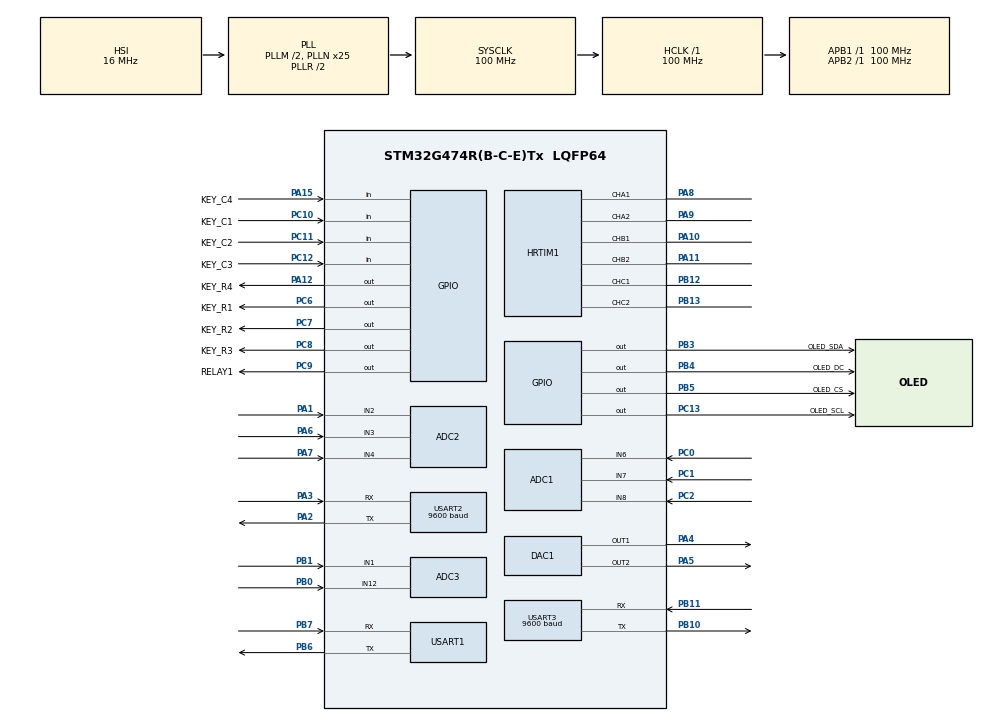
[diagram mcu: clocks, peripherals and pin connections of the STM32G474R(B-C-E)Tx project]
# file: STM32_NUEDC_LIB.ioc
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ADC1.Channel-12\#ChannelRegularConversion=ADC_CHANNEL_6
ADC1.Channel-13\#ChannelRegularConversion=ADC_CHANNEL_7
ADC1.Channel-17\#ChannelRegularConversion=ADC_CHANNEL_8
ADC1.ClockPrescaler=ADC_CLOCK_SYNC_PCLK_DIV4
ADC1.ContinuousConvMode=ENABLE
ADC1.DMAContinuousRequests=ENABLE
ADC1.EOCSelection=ADC_EOC_SEQ_CONV
ADC1.EnableAnalogWatchDog1=false
ADC1.EnableInjectedConversion=ENABLE
ADC1.EnableRegularConversion=ENABLE
ADC1.ExternalTrigInjecConv=ADC_EXTERNALTRIGINJEC_HRTIM_TRG2
ADC1.InjNumberOfConversion=3
ADC1.InjectedChannel-11\#ChannelInjectedConversion=ADC_CHANNEL_6
ADC1.InjectedChannel-14\#ChannelInjectedConversion=ADC_CHANNEL_7
ADC1.InjectedChannel-16\#ChannelInjectedConversion=ADC_CHANNEL_8
ADC1.InjectedConvMode=None
ADC1.InjectedOffsetNumber-11\#ChannelInjectedConversion=ADC_OFFSET_NONE
ADC1.InjectedOffsetNumber-14\#ChannelInjectedConversion=ADC_OFFSET_NONE
ADC1.InjectedOffsetNumber-16\#ChannelInjectedConversion=ADC_OFFSET_NONE
ADC1.InjectedRank-11\#ChannelInjectedConversion=1
ADC1.InjectedRank-14\#ChannelInjectedConversion=2
ADC1.InjectedRank-16\#ChannelInjectedConversion=3
ADC1.InjectedSamplingTime-11\#ChannelInjectedConversion=ADC_SAMPLETIME_47CYCLES_5
ADC1.InjectedSamplingTime-14\#ChannelInjectedConversion=ADC_SAMPLETIME_47CYCLES_5
ADC1.InjectedSamplingTime-16\#ChannelInjectedConversion=ADC_SAMPLETIME_47CYCLES_5
ADC1.NbrOfConversion=3
ADC1.NbrOfConversionFlag=1
ADC1.OffsetNumber-12\#ChannelRegularConversion=ADC_OFFSET_NONE
ADC1.OffsetNumber-13\#ChannelRegularConversion=ADC_OFFSET_NONE
ADC1.OffsetNumber-17\#ChannelRegularConversion=ADC_OFFSET_NONE
ADC1.Rank-12\#ChannelRegularConversion=1
ADC1.Rank-13\#ChannelRegularConversion=2
ADC1.Rank-17\#ChannelRegularConversion=3
ADC1.Rank2_Channel=ADC_CHANNEL_7
ADC1.Rank3_Channel=ADC_CHANNEL_8
ADC1.SamplingTime-12\#ChannelRegularConversion=ADC_SAMPLETIME_640CYCLES_5
ADC1.SamplingTime-13\#ChannelRegularConversion=ADC_SAMPLETIME_640CYCLES_5
ADC1.SamplingTime-17\#ChannelRegularConversion=ADC_SAMPLETIME_640CYCLES_5
ADC1.master=1
ADC2.Channel-12\#ChannelRegularConversion=ADC_CHANNEL_4
ADC2.Channel-6\#ChannelRegularConversion=ADC_CHANNEL_2
ADC2.Channel-7\#ChannelRegularConversion=ADC_CHANNEL_3
ADC2.ClockPrescaler=ADC_CLOCK_SYNC_PCLK_DIV4
ADC2.ContinuousConvMode=ENABLE
ADC2.DMAContinuousRequests=ENABLE
ADC2.EOCSelection=ADC_EOC_SEQ_CONV
ADC2.EnableInjectedConversion=ENABLE
ADC2.ExternalTrigInjecConv=ADC_EXTERNALTRIGINJEC_HRTIM_TRG4
ADC2.InjNumberOfConversion=3
ADC2.InjectedChannel-10\#ChannelInjectedConversion=ADC_CHANNEL_3
ADC2.InjectedChannel-11\#ChannelInjectedConversion=ADC_CHANNEL_4
ADC2.InjectedChannel-9\#ChannelInjectedConversion=ADC_CHANNEL_2
ADC2.InjectedOffsetNumber-10\#ChannelInjectedConversion=ADC_OFFSET_NONE
ADC2.InjectedOffsetNumber-11\#ChannelInjectedConversion=ADC_OFFSET_NONE
ADC2.InjectedOffsetNumber-9\#ChannelInjectedConversion=ADC_OFFSET_NONE
ADC2.InjectedRank-10\#ChannelInjectedConversion=2
ADC2.InjectedRank-11\#ChannelInjectedConversion=3
ADC2.InjectedRank-9\#ChannelInjectedConversion=1
ADC2.InjectedSamplingTime-10\#ChannelInjectedConversion=ADC_SAMPLETIME_47CYCLES_5
ADC2.InjectedSamplingTime-11\#ChannelInjectedConversion=ADC_SAMPLETIME_47CYCLES_5
ADC2.InjectedSamplingTime-9\#ChannelInjectedConversion=ADC_SAMPLETIME_47CYCLES_5
ADC2.NbrOfConversion=3
ADC2.NbrOfConversionFlag=1
ADC2.OffsetNumber-12\#ChannelRegularConversion=ADC_OFFSET_NONE
ADC2.OffsetNumber-6\#ChannelRegularConversion=ADC_OFFSET_NONE
ADC2.OffsetNumber-7\#ChannelRegularConversion=ADC_OFFSET_NONE
ADC2.Rank-12\#ChannelRegularConversion=3
ADC2.Rank-6\#ChannelRegularConversion=1
ADC2.Rank-7\#ChannelRegularConversion=2
ADC2.Rank1_Channel=ADC_CHANNEL_2
ADC2.Rank2_Channel=ADC_CHANNEL_3
ADC2.Rank3_Channel=ADC_CHANNEL_4
ADC2.SamplingTime-12\#ChannelRegularConversion=ADC_SAMPLETIME_640CYCLES_5
ADC2.SamplingTime-6\#ChannelRegularConversion=ADC_SAMPLETIME_640CYCLES_5
ADC2.SamplingTime-7\#ChannelRegularConversion=ADC_SAMPLETIME_640CYCLES_5
ADC3.Channel-0\#ChannelRegularConversion=ADC_CHANNEL_1
ADC3.Channel-4\#ChannelRegularConversion=ADC_CHANNEL_12
ADC3.ClockPrescaler=ADC_CLOCK_SYNC_PCLK_DIV4
ADC3.ContinuousConvMode=ENABLE
ADC3.DMAContinuousRequests=ENABLE
ADC3.EnableInjectedConversion=DISABLE
ADC3.ExternalTrigConv=ADC_EXTERNALTRIG_HRTIM_TRG3
ADC3.NbrOfConversion=2
ADC3.NbrOfConversionFlag=1
ADC3.OffsetNumber-0\#ChannelRegularConversion=ADC_OFFSET_NONE
ADC3.OffsetNumber-4\#ChannelRegularConversion=ADC_OFFSET_NONE
ADC3.Rank-0\#ChannelRegularConversion=1
ADC3.Rank-4\#ChannelRegularConversion=2
ADC3.Rank1_Channel=ADC_CHANNEL_1
ADC3.Rank2_Channel=ADC_CHANNEL_12
ADC3.Rank3_Channel=ADC_CHANNEL_1
ADC3.SamplingTime-0\#ChannelRegularConversion=ADC_SAMPLETIME_640CYCLES_5
ADC3.SamplingTime-4\#ChannelRegularConversion=ADC_SAMPLETIME_640CYCLES_5
ADC3.master=1
DAC1.DAC_Channel-DAC_OUT2=DAC_CHANNEL_2
DAC1.DAC_Trigger2_OUT1-DAC_OUT1=DAC_TRIGGER_NONE
DAC1.DAC_Trigger2_OUT2-DAC_OUT2=DAC_TRIGGER_NONE
DAC1.DAC_Trigger_OUT1-DAC_OUT1=DAC_TRIGGER_T6_TRGO
DAC1.DAC_Trigger_OUT2-DAC_OUT2=DAC_TRIGGER_T7_TRGO
Dma.ADC1.2.Direction=DMA_PERIPH_TO_MEMORY
Dma.ADC1.2.EventEnable=DISABLE
Dma.ADC1.2.Instance=DMA1_Channel3
Dma.ADC1.2.MemDataAlignment=DMA_MDATAALIGN_WORD
Dma.ADC1.2.MemInc=DMA_MINC_ENABLE
Dma.ADC1.2.Mode=DMA_CIRCULAR
Dma.ADC1.2.PeriphDataAlignment=DMA_PDATAALIGN_WORD
Dma.ADC1.2.PeriphInc=DMA_PINC_DISABLE
Dma.ADC1.2.Polarity=HAL_DMAMUX_REQ_GEN_RISING
Dma.ADC1.2.Priority=DMA_PRIORITY_LOW
Dma.ADC1.2.RequestNumber=1
Dma.ADC1.2.SignalID=NONE
Dma.ADC1.2.SyncEnable=DISABLE
Dma.ADC1.2.SyncPolarity=HAL_DMAMUX_SYNC_NO_EVENT
Dma.ADC1.2.SyncRequestNumber=1
Dma.ADC1.2.SyncSignalID=NONE
Dma.ADC2.4.Direction=DMA_PERIPH_TO_MEMORY
Dma.ADC2.4.EventEnable=DISABLE
Dma.ADC2.4.Instance=DMA1_Channel4
Dma.ADC2.4.MemDataAlignment=DMA_MDATAALIGN_WORD
Dma.ADC2.4.MemInc=DMA_MINC_ENABLE
Dma.ADC2.4.Mode=DMA_CIRCULAR
Dma.ADC2.4.PeriphDataAlignment=DMA_PDATAALIGN_WORD
Dma.ADC2.4.PeriphInc=DMA_PINC_DISABLE
Dma.ADC2.4.Polarity=HAL_DMAMUX_REQ_GEN_RISING
Dma.ADC2.4.Priority=DMA_PRIORITY_LOW
Dma.ADC2.4.RequestNumber=1
Dma.ADC2.4.SignalID=NONE
Dma.ADC2.4.SyncEnable=DISABLE
Dma.ADC2.4.SyncPolarity=HAL_DMAMUX_SYNC_NO_EVENT
Dma.ADC2.4.SyncRequestNumber=1
Dma.ADC2.4.SyncSignalID=NONE
Dma.ADC3.3.Direction=DMA_PERIPH_TO_MEMORY
Dma.ADC3.3.EventEnable=DISABLE
Dma.ADC3.3.Instance=DMA1_Channel5
Dma.ADC3.3.MemDataAlignment=DMA_MDATAALIGN_WORD
Dma.ADC3.3.MemInc=DMA_MINC_ENABLE
Dma.ADC3.3.Mode=DMA_CIRCULAR
Dma.ADC3.3.PeriphDataAlignment=DMA_PDATAALIGN_WORD
Dma.ADC3.3.PeriphInc=DMA_PINC_DISABLE
Dma.ADC3.3.Polarity=HAL_DMAMUX_REQ_GEN_RISING
Dma.ADC3.3.Priority=DMA_PRIORITY_LOW
Dma.ADC3.3.RequestNumber=1
Dma.ADC3.3.SignalID=NONE
Dma.ADC3.3.SyncEnable=DISABLE
Dma.ADC3.3.SyncPolarity=HAL_DMAMUX_SYNC_NO_EVENT
Dma.ADC3.3.SyncRequestNumber=1
Dma.ADC3.3.SyncSignalID=NONE
Dma.DAC1_CH1.5.Direction=DMA_MEMORY_TO_PERIPH
Dma.DAC1_CH1.5.EventEnable=DISABLE
Dma.DAC1_CH1.5.Instance=DMA1_Channel6
Dma.DAC1_CH1.5.MemDataAlignment=DMA_MDATAALIGN_WORD
Dma.DAC1_CH1.5.MemInc=DMA_MINC_ENABLE
Dma.DAC1_CH1.5.Mode=DMA_CIRCULAR
Dma.DAC1_CH1.5.PeriphDataAlignment=DMA_PDATAALIGN_WORD
Dma.DAC1_CH1.5.PeriphInc=DMA_PINC_DISABLE
Dma.DAC1_CH1.5.Polarity=HAL_DMAMUX_REQ_GEN_RISING
Dma.DAC1_CH1.5.Priority=DMA_PRIORITY_LOW
Dma.DAC1_CH1.5.RequestNumber=1
Dma.DAC1_CH1.5.SignalID=NONE
Dma.DAC1_CH1.5.SyncEnable=DISABLE
Dma.DAC1_CH1.5.SyncPolarity=HAL_DMAMUX_SYNC_NO_EVENT
Dma.DAC1_CH1.5.SyncRequestNumber=1
Dma.DAC1_CH1.5.SyncSignalID=NONE
Dma.DAC1_CH2.6.Direction=DMA_MEMORY_TO_PERIPH
Dma.DAC1_CH2.6.EventEnable=DISABLE
Dma.DAC1_CH2.6.Instance=DMA1_Channel7
Dma.DAC1_CH2.6.MemDataAlignment=DMA_MDATAALIGN_WORD
Dma.DAC1_CH2.6.MemInc=DMA_MINC_ENABLE
Dma.DAC1_CH2.6.Mode=DMA_CIRCULAR
Dma.DAC1_CH2.6.PeriphDataAlignment=DMA_PDATAALIGN_WORD
Dma.DAC1_CH2.6.PeriphInc=DMA_PINC_DISABLE
Dma.DAC1_CH2.6.Polarity=HAL_DMAMUX_REQ_GEN_RISING
Dma.DAC1_CH2.6.Priority=DMA_PRIORITY_LOW
Dma.DAC1_CH2.6.RequestNumber=1
Dma.DAC1_CH2.6.SignalID=NONE
Dma.DAC1_CH2.6.SyncEnable=DISABLE
Dma.DAC1_CH2.6.SyncPolarity=HAL_DMAMUX_SYNC_NO_EVENT
Dma.DAC1_CH2.6.SyncRequestNumber=1
Dma.DAC1_CH2.6.SyncSignalID=NONE
Dma.Request0=USART1_RX
Dma.Request1=USART1_TX
Dma.Request2=ADC1
Dma.Request3=ADC3
Dma.Request4=ADC2
Dma.Request5=DAC1_CH1
Dma.Request6=DAC1_CH2
Dma.Request7=USART2_RX
Dma.Request8=USART3_RX
Dma.USART1_RX.0.Direction=DMA_PERIPH_TO_MEMORY
Dma.USART1_RX.0.EventEnable=DISABLE
Dma.USART1_RX.0.Instance=DMA1_Channel1
Dma.USART1_RX.0.MemDataAlignment=DMA_MDATAALIGN_BYTE
Dma.USART1_RX.0.MemInc=DMA_MINC_ENABLE
Dma.USART1_RX.0.Mode=DMA_NORMAL
Dma.USART1_RX.0.PeriphDataAlignment=DMA_PDATAALIGN_BYTE
Dma.USART1_RX.0.PeriphInc=DMA_PINC_DISABLE
Dma.USART1_RX.0.Polarity=HAL_DMAMUX_REQ_GEN_RISING
Dma.USART1_RX.0.Priority=DMA_PRIORITY_LOW
Dma.USART1_RX.0.RequestNumber=1
Dma.USART1_RX.0.SignalID=NONE
Dma.USART1_RX.0.SyncEnable=DISABLE
Dma.USART1_RX.0.SyncPolarity=HAL_DMAMUX_SYNC_NO_EVENT
Dma.USART1_RX.0.SyncRequestNumber=1
Dma.USART1_RX.0.SyncSignalID=NONE
Dma.USART1_TX.1.Direction=DMA_MEMORY_TO_PERIPH
Dma.USART1_TX.1.EventEnable=DISABLE
Dma.USART1_TX.1.Instance=DMA1_Channel2
Dma.USART1_TX.1.MemDataAlignment=DMA_MDATAALIGN_BYTE
Dma.USART1_TX.1.MemInc=DMA_MINC_ENABLE
Dma.USART1_TX.1.Mode=DMA_NORMAL
Dma.USART1_TX.1.PeriphDataAlignment=DMA_PDATAALIGN_BYTE
Dma.USART1_TX.1.PeriphInc=DMA_PINC_DISABLE
Dma.USART1_TX.1.Polarity=HAL_DMAMUX_REQ_GEN_RISING
Dma.USART1_TX.1.Priority=DMA_PRIORITY_LOW
Dma.USART1_TX.1.RequestNumber=1
Dma.USART1_TX.1.SignalID=NONE
Dma.USART1_TX.1.SyncEnable=DISABLE
Dma.USART1_TX.1.SyncPolarity=HAL_DMAMUX_SYNC_NO_EVENT
Dma.USART1_TX.1.SyncRequestNumber=1
Dma.USART1_TX.1.SyncSignalID=NONE
Dma.USART2_RX.7.Direction=DMA_PERIPH_TO_MEMORY
Dma.USART2_RX.7.EventEnable=DISABLE
Dma.USART2_RX.7.Instance=DMA1_Channel8
Dma.USART2_RX.7.MemDataAlignment=DMA_MDATAALIGN_BYTE
Dma.USART2_RX.7.MemInc=DMA_MINC_ENABLE
Dma.USART2_RX.7.Mode=DMA_NORMAL
Dma.USART2_RX.7.PeriphDataAlignment=DMA_PDATAALIGN_BYTE
Dma.USART2_RX.7.PeriphInc=DMA_PINC_DISABLE
Dma.USART2_RX.7.Polarity=HAL_DMAMUX_REQ_GEN_RISING
Dma.USART2_RX.7.Priority=DMA_PRIORITY_LOW
Dma.USART2_RX.7.RequestNumber=1
Dma.USART2_RX.7.SignalID=NONE
Dma.USART2_RX.7.SyncEnable=DISABLE
Dma.USART2_RX.7.SyncPolarity=HAL_DMAMUX_SYNC_NO_EVENT
Dma.USART2_RX.7.SyncRequestNumber=1
Dma.USART2_RX.7.SyncSignalID=NONE
Dma.USART3_RX.8.Direction=DMA_PERIPH_TO_MEMORY
Dma.USART3_RX.8.EventEnable=DISABLE
Dma.USART3_RX.8.Instance=DMA2_Channel1
Dma.USART3_RX.8.MemDataAlignment=DMA_MDATAALIGN_BYTE
Dma.USART3_RX.8.MemInc=DMA_MINC_ENABLE
Dma.USART3_RX.8.Mode=DMA_NORMAL
Dma.USART3_RX.8.PeriphDataAlignment=DMA_PDATAALIGN_BYTE
Dma.USART3_RX.8.PeriphInc=DMA_PINC_DISABLE
Dma.USART3_RX.8.Polarity=HAL_DMAMUX_REQ_GEN_RISING
Dma.USART3_RX.8.Priority=DMA_PRIORITY_LOW
Dma.USART3_RX.8.RequestNumber=1
Dma.USART3_RX.8.SignalID=NONE
Dma.USART3_RX.8.SyncEnable=DISABLE
Dma.USART3_RX.8.SyncPolarity=HAL_DMAMUX_SYNC_NO_EVENT
Dma.USART3_RX.8.SyncRequestNumber=1
Dma.USART3_RX.8.SyncSignalID=NONE
HRTIM1.ADCTrigger2_Source1=HRTIM_ADCTRIGGEREVENT24_TIMERA_PERIOD
HRTIM1.ADCTrigger4_Source1=HRTIM_ADCTRIGGEREVENT24_TIMERB_PERIOD
HRTIM1.ADCTrigger_Id1=__NULL
HRTIM1.ADCTrigger_Id2=HRTIM_ADCTRIGGER_2
HRTIM1.ADCTrigger_Id3=__NULL
HRTIM1.ADCTrigger_Id4=HRTIM_ADCTRIGGER_4
HRTIM1.Adrom_TC=HRTIM_TIM_ADROM_CREST
HRTIM1.CompareUnit1-Output_TA1TA2=__NULL
HRTIM1.CompareUnit2-Output_TA1TA2=HRTIM_COMPAREUNIT_2
HRTIM1.CompareUnit2-Output_TB1TB2=HRTIM_COMPAREUNIT_2
HRTIM1.CompareUnit2-Output_TC1TC2=HRTIM_COMPAREUNIT_2
HRTIM1.CompareUnit3-Output_TC1TC2=__NULL
HRTIM1.CompareUnit4-Output_TB1TB2=__NULL
HRTIM1.CompareValue2-Output_TA1TA2=10000
HRTIM1.CompareValue2-Output_TB1TB2=5000
HRTIM1.CompareValue2-Output_TC1TC2=2000
HRTIM1.DeadTimeInsertion-Output_TA1TA2=HRTIM_TIMDEADTIMEINSERTION_ENABLED
HRTIM1.DeadTimeInsertion-Output_TB1TB2=HRTIM_TIMDEADTIMEINSERTION_ENABLED
HRTIM1.DeadTimeInsertion-Output_TC1TC2=HRTIM_TIMDEADTIMEINSERTION_ENABLED
HRTIM1.Deadtimeconfig-Output_TC1TC2=HRTIM_TIMERINDEX_TIMER_C
HRTIM1.Event_EEV1=__NULL
HRTIM1.Event_EEV2=__NULL
HRTIM1.FallingValue-Output_TA1TA2=50
HRTIM1.FallingValue-Output_TB1TB2=50
HRTIM1.FallingValue-Output_TC1TC2=50
HRTIM1.Ferom_TC=HRTIM_TIM_FEROM_VALLEY
HRTIM1.HRTIMInterruptResquests1=HRTIM_IT_NONE
HRTIM1.HRTIMInterruptResquests2=HRTIM_IT_NONE
HRTIM1.InterruptRequests1-Output_TC1TC2=HRTIM_TIM_IT_RST
HRTIM1.NumberADCTriggerSource2=1
HRTIM1.NumberADCTriggerSource4=1
HRTIM1.NumberInterruptRequests-Output_TC1TC2=1
HRTIM1.NumberResetSource1-Output_TA1TA2=1
HRTIM1.NumberResetSource1-Output_TB1TB2=1
HRTIM1.NumberResetSource1-Output_TC1TC2=1
HRTIM1.NumberResetSource2_TC=0
HRTIM1.NumberResetTrigger-Output_TA1TA2=0
HRTIM1.NumberSetSource1-Output_TA1TA2=1
HRTIM1.NumberSetSource1-Output_TB1TB2=1
HRTIM1.NumberSetSource1-Output_TC1TC2=1
HRTIM1.NumberSetSource2_TA=0
HRTIM1.NumberSetSource2_TC=0
HRTIM1.ORingUpdateSource_ADCTrigger4=HRTIM_ADCTRIGGERUPDATE_TIMER_B
HRTIM1.Outrom_TC=HRTIM_TIM_OUTROM_VALLEY
HRTIM1.Periode_TA=2500
HRTIM1.Periode_TB=5000
HRTIM1.Periode_TC=2000
HRTIM1.PrescalerDead-Output_TA1TA2=HRTIM_TIMDEADTIME_PRESCALERRATIO_DIV1
HRTIM1.PrescalerDead-Output_TB1TB2=HRTIM_TIMDEADTIME_PRESCALERRATIO_DIV1
HRTIM1.PrescalerDead-Output_TC1TC2=HRTIM_TIMDEADTIME_PRESCALERRATIO_DIV1
HRTIM1.PrescalerRatio_TA=HRTIM_PRESCALERRATIO_DIV1
HRTIM1.PrescalerRatio_TB=HRTIM_PRESCALERRATIO_DIV1
HRTIM1.PrescalerRatio_TC=HRTIM_PRESCALERRATIO_DIV1
HRTIM1.ResetOutput1_Source1-Output_TA1TA2=HRTIM_OUTPUTRESET_TIMCMP2
HRTIM1.ResetOutput1_Source1-Output_TB1TB2=HRTIM_OUTPUTRESET_TIMCMP2
HRTIM1.ResetOutput1_Source1-Output_TC1TC2=HRTIM_OUTPUTRESET_TIMCMP2
HRTIM1.RisingValue-Output_TA1TA2=50
HRTIM1.RisingValue-Output_TB1TB2=50
HRTIM1.RisingValue-Output_TC1TC2=50
HRTIM1.SetOutput1_Source1-Output_TA1TA2=HRTIM_OUTPUTSET_TIMPER
HRTIM1.SetOutput1_Source1-Output_TB1TB2=HRTIM_OUTPUTSET_TIMPER
HRTIM1.SetOutput1_Source1-Output_TC1TC2=HRTIM_OUTPUTSET_TIMPER
HRTIM1.UpDownMode-Output_TC1TC2=HRTIM_TIMERUPDOWNMODE_UPDOWN
HRTIM1.postscaler2=0
HRTIM1.rom_TC=HRTIM_TIM_ROM_CREST
Mcu.Family=STM32G4
Mcu.Name=STM32G474R(B-C-E)Tx
Mcu.Package=LQFP64
NVIC.ADC1_2_IRQn=true\:0\:0\:false\:false\:true\:true\:true\:true
NVIC.ADC3_IRQn=true\:0\:0\:false\:false\:true\:true\:true\:true
NVIC.DMA1_Channel1_IRQn=true\:0\:0\:false\:false\:true\:false\:true\:true
NVIC.DMA1_Channel2_IRQn=true\:0\:0\:false\:false\:true\:false\:true\:true
NVIC.DMA1_Channel3_IRQn=true\:1\:0\:true\:false\:true\:false\:true\:true
NVIC.DMA1_Channel4_IRQn=true\:1\:0\:true\:false\:true\:false\:true\:true
NVIC.DMA1_Channel5_IRQn=true\:1\:0\:true\:false\:true\:false\:true\:true
NVIC.DMA1_Channel6_IRQn=true\:0\:0\:false\:false\:true\:false\:true\:true
NVIC.DMA1_Channel7_IRQn=true\:0\:0\:false\:false\:true\:false\:true\:true
NVIC.DMA1_Channel8_IRQn=true\:0\:0\:false\:false\:true\:false\:true\:true
NVIC.DMA2_Channel1_IRQn=true\:0\:0\:false\:false\:true\:false\:true\:true
NVIC.HRTIM1_TIMC_IRQn=true\:0\:0\:false\:false\:true\:true\:true\:true
NVIC.PriorityGroup=NVIC_PRIORITYGROUP_4
NVIC.TIM1_UP_TIM16_IRQn=true\:0\:0\:false\:false\:true\:true\:true\:true
NVIC.TIM6_DAC_IRQn=true\:0\:0\:false\:false\:true\:true\:true\:true
NVIC.TIM7_DAC_IRQn=true\:0\:0\:false\:false\:true\:true\:true\:true
NVIC.TIM8_UP_IRQn=true\:0\:0\:false\:false\:true\:true\:true\:true
NVIC.USART1_IRQn=true\:0\:0\:true\:false\:true\:true\:true\:true
NVIC.USART2_IRQn=true\:0\:0\:false\:false\:true\:true\:true\:true
NVIC.USART3_IRQn=true\:0\:0\:false\:false\:true\:true\:true\:true
PA1.Mode=IN2-Single-Ended
PA1.Signal=ADC2_IN2
PA10.Mode=Output_TB1TB2
PA10.Signal=HRTIM1_CHB1
PA11.Mode=Output_TB1TB2
PA11.Signal=HRTIM1_CHB2
PA12.GPIO_Label=KEY_R4
PA12.Signal=GPIO_Output
PA13.Mode=Serial_Wire
PA13.Signal=SYS_JTMS-SWDIO
PA14.Mode=Serial_Wire
PA14.Signal=SYS_JTCK-SWCLK
PA15.GPIO_Label=KEY_C4
PA15.GPIO_PuPd=GPIO_PULLDOWN
PA15.Signal=GPIO_Input
PA2.Mode=Asynchronous
PA2.Signal=USART2_TX
PA3.Mode=Asynchronous
PA3.Signal=USART2_RX
PA4.Signal=COMP_DAC11_group
PA5.Signal=COMP_DAC12_group
PA6.Mode=IN3-Single-Ended
PA6.Signal=ADC2_IN3
PA7.Mode=IN4-Single-Ended
PA7.Signal=ADC2_IN4
PA8.Mode=Output_TA1TA2
PA8.Signal=HRTIM1_CHA1
PA9.Mode=Output_TA1TA2
PA9.Signal=HRTIM1_CHA2
PB0.Mode=IN12-Single-Ended
PB0.Signal=ADC3_IN12
PB1.Mode=IN1-Single-Ended
PB1.Signal=ADC3_IN1
PB10.Mode=Asynchronous
PB10.Signal=USART3_TX
PB11.Mode=Asynchronous
PB11.Signal=USART3_RX
PB12.Mode=Output_TC1TC2
PB12.Signal=HRTIM1_CHC1
PB13.Mode=Output_TC1TC2
PB13.Signal=HRTIM1_CHC2
PB3.GPIO_Label=OLED_SDA
PB3.GPIO_Speed=GPIO_SPEED_FREQ_VERY_HIGH
PB3.Signal=GPIO_Output
PB4.GPIO_Label=OLED_DC
PB4.GPIO_Speed=GPIO_SPEED_FREQ_VERY_HIGH
PB4.Signal=GPIO_Output
PB5.GPIO_Label=OLED_CS
PB5.GPIO_Speed=GPIO_SPEED_FREQ_VERY_HIGH
PB5.Signal=GPIO_Output
PB6.Mode=Asynchronous
PB6.Signal=USART1_TX
PB7.Mode=Asynchronous
PB7.Signal=USART1_RX
PC0.Mode=IN6-Single-Ended
PC0.Signal=ADC1_IN6
PC1.Mode=IN7-Single-Ended
PC1.Signal=ADC1_IN7
PC10.GPIO_Label=KEY_C1
PC10.GPIO_PuPd=GPIO_PULLDOWN
PC10.Signal=GPIO_Input
PC11.GPIO_Label=KEY_C2
PC11.GPIO_PuPd=GPIO_PULLDOWN
PC11.Signal=GPIO_Input
PC12.GPIO_Label=KEY_C3
PC12.GPIO_PuPd=GPIO_PULLDOWN
PC12.Signal=GPIO_Input
PC13.GPIO_Label=OLED_SCL
PC13.Signal=GPIO_Output
PC2.Mode=IN8-Single-Ended
PC2.Signal=ADC1_IN8
PC6.GPIO_Label=KEY_R1
PC6.Signal=GPIO_Output
PC7.GPIO_Label=KEY_R2
PC7.Signal=GPIO_Output
PC8.GPIO_Label=KEY_R3
PC8.Signal=GPIO_Output
PC9.GPIO_Label=RELAY1
PC9.PinState=GPIO_PIN_SET
PC9.Signal=GPIO_Output
PF0-OSC_IN.Mode=HSE-External-Oscillator
PF0-OSC_IN.Signal=RCC_OSC_IN
PF1-OSC_OUT.Mode=HSE-External-Oscillator
PF1-OSC_OUT.Signal=RCC_OSC_OUT
ProjectManager.HeapSize=0x200
ProjectManager.StackSize=0x400
ProjectManager.TargetToolchain=STM32CubeIDE
RCC.ADC12Freq_Value=100000000
RCC.ADC345Freq_Value=100000000
RCC.AHBFreq_Value=100000000
RCC.APB1Freq_Value=100000000
RCC.APB1TimFreq_Value=100000000
RCC.APB2Freq_Value=100000000
RCC.APB2TimFreq_Value=100000000
RCC.CortexFreq_Value=100000000
RCC.EXTERNAL_CLOCK_VALUE=12288000
RCC.HCLKFreq_Value=100000000
RCC.HSE_VALUE=8000000
RCC.HSI48_VALUE=48000000
RCC.HSI_VALUE=16000000
RCC.LSE_VALUE=32768
RCC.PLLM=RCC_PLLM_DIV2
RCC.PLLN=25
RCC.SYSCLKFreq_VALUE=100000000
RCC.SYSCLKSource=RCC_SYSCLKSOURCE_PLLCLK
RCC.USBFreq_Value=100000000
RCC.VCOOutputFreq_Value=200000000
SH.COMP_DAC11_group.0=DAC1_OUT1,DAC_OUT1
SH.COMP_DAC12_group.0=DAC1_OUT2,DAC_OUT2
STMicroelectronics.X-CUBE-ALGOBUILD.1.3.0.LibraryCcDSPOoLibraryJjDSPOoLibrary=true
TIM1.AutoReloadPreload=TIM_AUTORELOAD_PRELOAD_ENABLE
TIM1.PeriodNoDither=50000-1
TIM6.AutoReloadPreload=TIM_AUTORELOAD_PRELOAD_ENABLE
TIM6.PeriodNoDither=5000-1
TIM6.Prescaler=0
TIM6.TIM_MasterOutputTrigger=TIM_TRGO_UPDATE
TIM7.AutoReloadPreload=TIM_AUTORELOAD_PRELOAD_ENABLE
TIM7.PeriodNoDither=5000-1
TIM7.Prescaler=10-1
TIM7.TIM_MasterOutputTrigger=TIM_TRGO_UPDATE
TIM8.AutoReloadPreload=TIM_AUTORELOAD_PRELOAD_ENABLE
TIM8.PeriodNoDither=100-1
USART1.VirtualMode-Asynchronous=VM_ASYNC
USART2.BaudRate=9600
USART2.VirtualMode-Asynchronous=VM_ASYNC
USART3.BaudRate=9600
USART3.VirtualMode-Asynchronous=VM_ASYNC
VP_STMicroelectronics.X-CUBE-ALGOBUILD_VS_DSPOoLibraryJjLibrary_1.3.0_1.3.0.Mode=DSPOoLibraryJjLibrary
VP_SYS_VS_DBSignals.Mode=DisableDeadBatterySignals
VP_TIM1_VS_ClockSourceINT.Mode=Internal
VP_TIM6_VS_ClockSourceINT.Mode=Enable_Timer
VP_TIM7_VS_ClockSourceINT.Mode=Enable_Timer
VP_TIM8_VS_ClockSourceINT.Mode=Internal
board=custom

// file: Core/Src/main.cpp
/* USER CODE BEGIN Header */
/**
 ******************************************************************************
 * @file           : main.c
 * @brief          : Main program body
 ******************************************************************************
 * @attention
 *
 * Copyright (c) 2025 STMicroelectronics.
 * All rights reserved.
 *
 * This software is licensed under terms that can be found in the LICENSE file
 * in the root directory of this software component.
 * If no LICENSE file comes with this software, it is provided AS-IS.
 *
 ******************************************************************************
 */
/* USER CODE END Header */
#include "main.h"
#include "adc.h"
#include "dac.h"
#include "dma.h"
#include "hrtim.h"
#include "tim.h"
#include "usart.h"
#include "gpio.h"
/* USER CODE BEGIN Includes */
#include "stm32_hrtim_pwm.h"
#include "stm32_adc.h"
#include "stm32_relay.h"
#include "stm32_test.h"
#include "stm32_message.h"
#include "stm32_dc_dc.h"
#include "SEGGER_SYSVIEW.h"
#include "SEGGER_SYSVIEW_Conf.h"
#include "2015.h"
#include "flt_fir_hilbert.h"
#include "hw_port_dac.h"
/* USER CODE END Includes */

void SystemClock_Config(void);

int main(void)
{

  /* MCU Configuration--------------------------------------------------------*/

  /* Reset of all peripherals, Initializes the Flash interface and the Systick. */
  HAL_Init();

  /* Configure the system clock */
  SystemClock_Config();

  /* USER CODE BEGIN SysInit */
//  stm32_test::segger_systemview_test_enable();
  /* USER CODE END SysInit */

  /* Initialize all configured peripherals */
  MX_GPIO_Init();
  MX_DMA_Init();
  MX_ADC1_Init();
  MX_HRTIM1_Init();
  MX_USART1_UART_Init();
  MX_ADC2_Init();
  MX_ADC3_Init();
  MX_TIM1_Init();
  MX_DAC1_Init();
  MX_TIM6_Init();
  MX_TIM7_Init();
  MX_TIM8_Init();
  MX_USART2_UART_Init();
  MX_USART3_UART_Init();
  /* USER CODE BEGIN 2 */
  //  stm32_test::filiter_hilbert_test();
  //  stm32_test::dac1_dma_test();
  //  stm32_test::pll_init_test();
  //    stm32_test::mk1031_sensor_test();
  //  stm32_test::timerA_pwm_test();
  //  stm32_test::vofa_receive_test();
  //  stm32_test::mk1031_sensor_test();
  //    stm32_test::timerA_pwm_test();
  //    stm32_test::dc_dc_currentClosedLoop_test();
  //    stm32_test::oled_test();
  //  stm32_test::nuedc_2015_loop_test();//校赛测试
  //  stm32_test::dc_dc_current_voltage_ClosedLoop_test();
  //  stm32_test::mk1031_sensor_test();
  //    stm32_test::dc_dc_openLoop_test();
  //  stm32_test::boost_currentClosedLoop_test();
  //    stm32_test::boost_CurrentVoltageClosedLoop_test();
  //      stm32_test::boost_VoltageClosedLoop_test();
  //    stm32_test::boost_currentClosedLoop_test();
  //    stm32_test::boost_openLoop_test();
//    stm32_test::vofa_receive_test();
    stm32_test::vofa_send_test();
  //  stm32_test::dc_ac_openLoop_test();
//  stm32_test::dac1_dma_test_20khz();
  //  stm32_test::timerC_center_align_pwm_test();
  /* USER CODE END 2 */

  /* Infinite loop */
  while (1)
    {

      //      stm32_test::dc_dc_openLoop_test();
      //      nuedc_2015::loop();
      //      stm32_test::us_timer_test();

    }
}

void SystemClock_Config(void)
{
  RCC_OscInitTypeDef RCC_OscInitStruct = {0};
  RCC_ClkInitTypeDef RCC_ClkInitStruct = {0};

  /** Configure the main internal regulator output voltage
   */
  HAL_PWREx_ControlVoltageScaling(PWR_REGULATOR_VOLTAGE_SCALE1);

  /** Initializes the RCC Oscillators according to the specified parameters
   * in the RCC_OscInitTypeDef structure.
   */
  RCC_OscInitStruct.OscillatorType = RCC_OSCILLATORTYPE_HSI;
  RCC_OscInitStruct.HSIState = RCC_HSI_ON;
  RCC_OscInitStruct.HSICalibrationValue = RCC_HSICALIBRATION_DEFAULT;
  RCC_OscInitStruct.PLL.PLLState = RCC_PLL_ON;
  RCC_OscInitStruct.PLL.PLLSource = RCC_PLLSOURCE_HSI;
  RCC_OscInitStruct.PLL.PLLM = RCC_PLLM_DIV2;
  RCC_OscInitStruct.PLL.PLLN = 25;
  RCC_OscInitStruct.PLL.PLLP = RCC_PLLP_DIV2;
  RCC_OscInitStruct.PLL.PLLQ = RCC_PLLQ_DIV2;
  RCC_OscInitStruct.PLL.PLLR = RCC_PLLR_DIV2;
  if (HAL_RCC_OscConfig(&RCC_OscInitStruct) != HAL_OK)
    {
      Error_Handler();
    }

  /** Initializes the CPU, AHB and APB buses clocks
   */
  RCC_ClkInitStruct.ClockType = RCC_CLOCKTYPE_HCLK|RCC_CLOCKTYPE_SYSCLK
      |RCC_CLOCKTYPE_PCLK1|RCC_CLOCKTYPE_PCLK2;
  RCC_ClkInitStruct.SYSCLKSource = RCC_SYSCLKSOURCE_PLLCLK;
  RCC_ClkInitStruct.AHBCLKDivider = RCC_SYSCLK_DIV1;
  RCC_ClkInitStruct.APB1CLKDivider = RCC_HCLK_DIV1;
  RCC_ClkInitStruct.APB2CLKDivider = RCC_HCLK_DIV1;

  if (HAL_RCC_ClockConfig(&RCC_ClkInitStruct, FLASH_LATENCY_3) != HAL_OK)
    {
      Error_Handler();
    }
}

void Error_Handler(void)
{
  __disable_irq();
  while (1)
    {
    }
}
